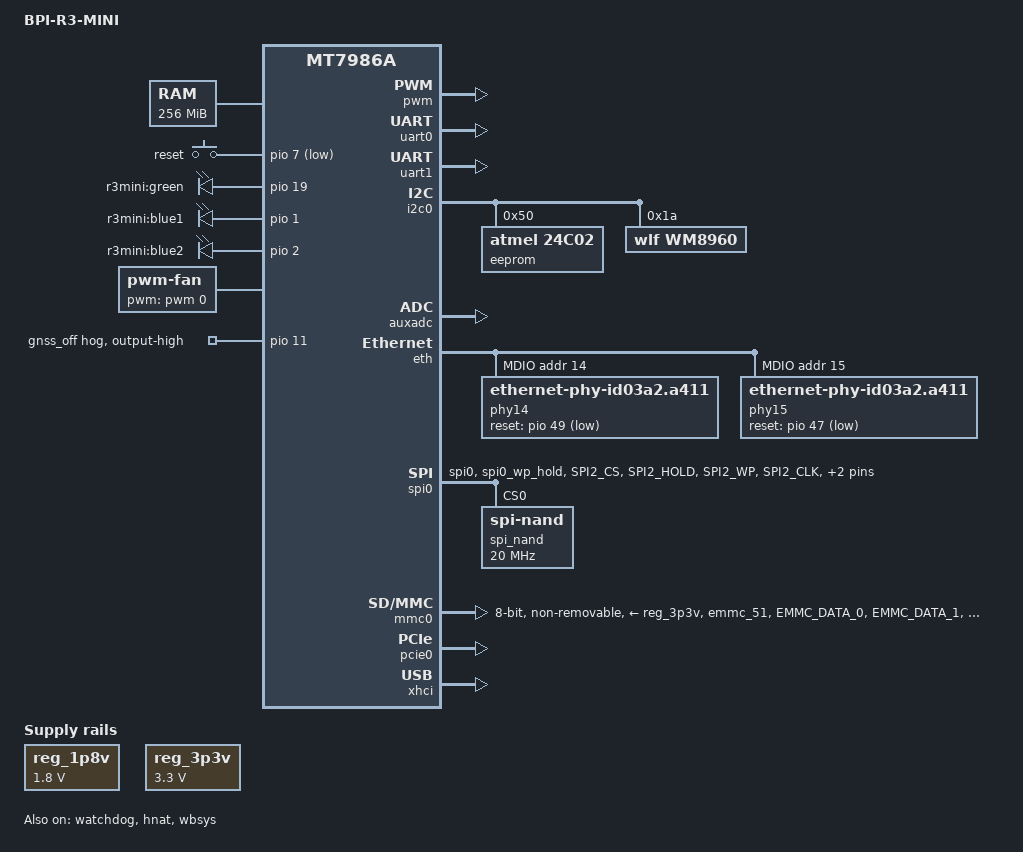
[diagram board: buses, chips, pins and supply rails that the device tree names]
/dts-v1/;
#include "mt7986a.dtsi"
#include "mt7986a-pinctrl.dtsi"
#include <dt-bindings/input/input.h>
#include <dt-bindings/gpio/gpio.h>
/ {
	model = "BPI-R3-MINI";
	compatible = "bananapi,bpi-r3mini-emmc", "mediatek,mt7986a";

	aliases {
		led-boot = &status_led;
		led-failsafe = &status_led;
		led-running = &status_led;
		led-upgrade = &status_led;
	};

	chosen {
		bootargs = "console=ttyS0,115200n1 loglevel=8 \
		earlycon=uart8250,mmio32,0x11002000 \
		root=PARTLABEL=rootfs rootwait rootfstype=squashfs,f2fs";
	};

	memory {
		reg = <0 0x40000000 0 0x10000000>;
	};

	gpio-keys {
		compatible = "gpio-keys";

		button-reset {
			label = "reset";
			linux,code = <KEY_RESTART>;
			gpios = <&pio 7 GPIO_ACTIVE_LOW>;
		};
	};

	leds {
		compatible = "gpio-leds";

		status_led: green {
			label = "r3mini:green";
			gpios = <&pio 19 GPIO_ACTIVE_HIGH>;
		};

		led-1 {
			label = "r3mini:blue1";
			gpios = <&pio 1 GPIO_ACTIVE_HIGH>;
			default-state = "on";
		};

		led-2 {
			label = "r3mini:blue2";
			gpios = <&pio 2 GPIO_ACTIVE_HIGH>;
			default-state = "on";
		};
	};

	fan: pwm-fan {
		compatible = "pwm-fan";
		#cooling-cells = <2>;
		cooling-levels = <0 64 128 192>;
		pwms = <&pwm 0 10000 0>;
		status = "okay";
	};

        reg_1p8v: regulator-1p8v {
                compatible = "regulator-fixed";
                regulator-name = "fixed-1.8V";
                regulator-min-microvolt = <1800000>;
                regulator-max-microvolt = <1800000>;
                regulator-boot-on;
                regulator-always-on;
        };

        reg_3p3v: regulator-3p3v {
                compatible = "regulator-fixed";
                regulator-name = "fixed-3.3V";
                regulator-min-microvolt = <3300000>;
                regulator-max-microvolt = <3300000>;
                regulator-boot-on;
                regulator-always-on;
        };

	sound {
		compatible = "mediatek,mt7986-wm8960-machine";
		mediatek,platform = <&afe>;
		audio-routing = "Headphone", "HP_L",
				"Headphone", "HP_R",
				"LINPUT1", "AMIC",
				"RINPUT1", "AMIC";
		mediatek,audio-codec = <&wm8960>;
		status = "okay";
	};
};

&pwm {
	pinctrl-names = "default";
	pinctrl-0 = <&pwm0_pin &pwm1_pin_g1>;
	status = "okay";
};

&uart0 {
	status = "okay";
};

&uart1 {
	pinctrl-names = "default";
	pinctrl-0 = <&uart1_pins>;
	status = "okay";
};

&uart2 {
	pinctrl-names = "default";
	pinctrl-0 = <&uart2_pins>;
	status = "disabled";
};

&i2c0 {
	pinctrl-names = "default";
	pinctrl-0 = <&i2c_pins>;
	status = "okay";

	/* MAC Address EEPROM */
        eeprom@50 {
                compatible = "atmel,24c02";
                reg = <0x50>;

                address-bits = <8>;
                page-size = <8>;
                size = <256>;
        };

	wm8960: wm8960@1a {
		compatible = "wlf,wm8960";
		reg = <0x1a>;
	};
};

&auxadc {
	status = "okay";
};

&watchdog {
	status = "okay";
};

&cpu_thermal {
	trips {
		cpu_trip_critical: critical {
			temperature = <95000>;
			hysteresis = <2000>;
			type = "critical";
		};

		cpu_trip_hot: hot {
			temperature = <40000>;
			hysteresis = <2000>;
			type = "hot";
		};

		cpu_trip_active: active {
			temperature = <35000>;
			hysteresis = <2000>;
			type = "active";
		};

		cpu_trip_passive: passive {
			temperature = <20000>;
			hysteresis = <2000>;
			type = "passive";
		};
	};

	cooling-maps {
		cpu-active-high {
			cooling-device = <&fan 3 3>;
			trip = <&cpu_trip_critical>;
		};

		cpu-active-low {
			cooling-device = <&fan 2 2>;
			trip = <&cpu_trip_hot>;
		};

		cpu-active {
			cooling-device = <&fan 1 1>;
			trip = <&cpu_trip_active>;
		};

		cpu-passive {
			cooling-device = <&fan 0 0>;
			trip = <&cpu_trip_passive>;
		};
	};
};

&eth {
	status = "okay";

	gmac0: mac@0 {

		compatible = "mediatek,eth-mac";
		reg = <0>;
		phy-mode = "2500base-x";

		fixed-link {
			speed = <2500>;
			full-duplex;
			pause;
		};
	};

	gmac1: mac@1 {

		compatible = "mediatek,eth-mac";
		reg = <1>;
		phy-mode = "2500base-x";

		fixed-link {
			speed = <2500>;
			full-duplex;
			pause;
		};
	};

	mdio: mdio-bus {
		#address-cells = <1>;
		#size-cells = <0>;

		phy14: phy@14 {
			/* EN8811H PHY ID */
			compatible = "ethernet-phy-id03a2.a411";
			/* PHY Address */
			reg = <14>;
			reset-gpios = <&pio 49 1>;     /* GPIO49 */
			reset-assert-us = <10000>;
			reset-deassert-us = <20000>;
			phy-mode = "2500base-x";
			full-duplex;
			pause;
		};

		phy15: phy@15 {
			/* EN8811H PHY ID */
			compatible = "ethernet-phy-id03a2.a411";
			/* PHY Address */
			reg = <15>;
			reset-gpios = <&pio 47 1>;     /* GPIO47 */
			reset-assert-us = <10000>;
			reset-deassert-us = <20000>;
			phy-mode = "2500base-x";
			full-duplex;
			pause;
		};
	};
};

&hnat {
	mtketh-wan = "eth1";
	mtketh-lan = "eth0";
	mtketh-max-gmac = <2>;
	status = "okay";
};

&spi0 {
	pinctrl-names = "default";
	pinctrl-0 = <&spi_flash_pins>;
	status = "okay";

	spi_nand: flash@0 {
		#address-cells = <1>;
		#size-cells = <1>;
		compatible = "spi-nand";
		reg = <0>;
		spi-max-frequency = <20000000>;
		spi-tx-bus-width = <4>;
		spi-rx-bus-width = <4>;
	};
};

&spi1 {
	pinctrl-names = "default";
	pinctrl-0 = <&spic_pins_g2>;
	status = "disabled";
};

&mmc0 {
        pinctrl-names = "default", "state_uhs";
        pinctrl-0 = <&mmc0_pins_default>;
        pinctrl-1 = <&mmc0_pins_uhs>;
        bus-width = <8>;
        max-frequency = <200000000>;
        cap-mmc-highspeed;
        mmc-hs200-1_8v;
        mmc-hs400-1_8v;
        hs400-ds-delay = <0x14014>;
        vmmc-supply = <&reg_3p3v>;
        vqmmc-supply = <&reg_1p8v>;
        non-removable;
        no-sd;
        no-sdio;
        status = "okay";
};

&pcie0 {
	pinctrl-names = "default";
	pinctrl-0 = <&pcie0_pins>;
	status = "okay";
};

&wbsys {
	status = "okay";
	mediatek,eeprom-data = <0x86790200 0x000c4326 0x60000000 0x00000000 0x00000000 0x00000000 0x00000000 0x00000000
		0x00000000 0x00000000 0x00000000 0x00000000 0x00000000 0x00000000 0x00000000 0x00000000
		0x00000000 0x00000000 0x00000000 0x00000000 0x00000000 0x00000000 0x00000000 0x00000000
		0x00000000 0x00000000 0x00000000 0x00000000 0x00000000 0x00000000 0x00000000 0x00000000
		0x00000000 0x00000000 0x00000000 0x00000000 0x00000000 0x00000000 0x00000000 0x00000000
		0x00000000 0x00000000 0x00000000 0x00000000 0x00000000 0x00000000 0x00000000 0x00000000
		0x00000000 0x00000000 0x00000000 0x00000000 0x00000000 0x00000000 0x00000000 0x00000000
		0x00000000 0x00000000 0x00000000 0x00000000 0x00000000 0x00000000 0x00000000 0x00000000
		0x00000000 0x00000000 0x00000000 0x00000000 0x00000000 0x00000000 0x00000000 0x00000000
		0x00000000 0x00000000 0x00000000 0x00000000 0x00000000 0x00000000 0x00000000 0x00000000
		0x00000000 0x00000000 0x00000000 0x00000000 0x00000000 0x00000000 0x00000000 0x00000000
		0x00000000 0x00000000 0x00000000 0x00000000 0x00000000 0x00000000 0x00000000 0x00000000
		0x00000000 0x00000000 0x00000000 0x00000000 0x125b486c 0x00280000 0x05d00000 0x00000000
		0x00000000 0x00000000 0x00000000 0x00000000 0x00000000 0x00000000 0x00000000 0x00000000
		0x00000000 0x00000000 0x00000000 0x00000000 0x00000000 0x00000000 0x00000000 0x00000000
		0x00000000 0x00000000 0x00000000 0x00000000 0x00000000 0x00000000 0x00000000 0x00000000
		0x00000000 0x00000000 0x00000000 0x00000000 0x00000000 0x00000000 0x00000000 0x00000000
		0x00000000 0x00000000 0x00000000 0x00000000 0x00000000 0x00000000 0x00000000 0x00000000
		0x00000000 0x00000000 0x00000000 0x00000000 0x00000000 0x00000000 0x00000000 0x00000000
		0x00000000 0x00000000 0x00000000 0x00000000 0x0c000000 0x00000000 0x00000000 0x00000000
		0x00000000 0x00000000 0x00000000 0x00000000 0x00000000 0x00000000 0x00000000 0x00000000
		0x00000000 0x00000000 0x00000000 0x00000000 0x00000000 0x00000000 0x00000000 0x00000000
		0x00000000 0x00000000 0x00000000 0x00000000 0x00000000 0x00000000 0x00000000 0x00000000
		0x00000000 0x00000000 0x00000000 0x00000000 0x00000000 0x00000000 0x00000000 0x00000000
		0x00000000 0x00000000 0x00000000 0x00000000 0x00000000 0x00000000 0x00000000 0x00000000
		0x00000000 0x00000000 0x00000000 0x00000000 0x00000000 0x00000000 0x00000000 0x00000000
		0x00000000 0x00000000 0x00000000 0x00000000 0x00000000 0x00000000 0x00000000 0x00000000
		0x00000000 0x00000000 0x00000000 0x00000000 0x00000000 0x00000000 0x00000000 0x00000000
		0x00000000 0x00000000 0x00000000 0x00000000 0x00000000 0x00000000 0x00000000 0x00000000
		0x00000000 0x00000000 0x00000000 0x00000000 0x00000000 0x00000000 0x00000000 0x00000000
		0x00000000 0x00000000 0x00000000 0x00000000 0x00000000 0x00000000 0x00000000 0x00000000
		0x00000000 0x00000012 0x12120000 0x00000000 0x00000000 0x00002222 0x22223333 0x33333333
		0x33333333 0x33333333 0x33333333 0x33333333 0x33333333 0x33330000 0x00000000 0x00000000
		0x00000000 0x00000000 0x00000000 0x00000000 0x00000000 0x00000000 0x00000000 0x00000000
		0x002b2b2b 0x2b2d2d2d 0x2d2d2d2d 0x2d2d2d2d 0x2d2d2d2d 0x2d2d2d2d 0x2d000000 0x00000000
		0x00000000 0x00242424 0x24222222 0x22242424 0x24222222 0x22242424 0x24222222 0x22242424
		0x24222222 0x22000000 0x00000000 0x00000000 0x00000000 0x00000000 0x00000000 0x00000000
		0x00000000 0x00000000 0x00000000 0x00000000 0x00000000 0x00000000 0x00000000 0x00000000
		0x00000000 0x00000000 0x00000000 0x00000000 0x00000000 0x00000000 0x00000000 0x00000000
		0x00000000 0x00000000 0x00000000 0x00000000 0x00000000 0x00000000 0x00000000 0x00000000
		0x00000000 0x00000000 0x00000000 0x00000000 0x00000000 0x00000000 0x00000000 0x00000000
		0x00000000 0x00000000 0x00000000 0x00000000 0x00000000 0x00000000 0x00000000 0x00000000
		0x00000000 0x00000000 0x00000000 0x00000000 0x00000000 0x00000000 0x00000000 0x00000000
		0x00000000 0x00000000 0x00000000 0x00000000 0x00000000 0x00000000 0x00000000 0x00000000
		0x00000000 0x007f7f7f 0xd1d1dddd 0xe9e9f5f5 0x01010909 0x1515d1d1 0xdddde9e9 0xf5f5fdfd
		0x09091515 0xd1d1dddd 0xe9e9f5f5 0xfdfd0909 0x1515d1d1 0xdddde9e9 0xf5f5fdfd 0x09091515
		0x00000000 0x00000000 0x00000000 0x00000000 0x00000000 0x00000000 0x00000000 0x00000000
		0x00000000 0x00000000 0x00000000 0x00000000 0x00000000 0x00000000 0x00000000 0x00000000
		0x0efefc00 0x00000000 0x00000000 0x00000000 0x00000000 0x00000000 0x00000000 0x00000000
		0x00000000 0x00000000 0x00000000 0x00000000 0x00000000 0x00000000 0x00000000 0x00000000
		0x00000000 0x00000000 0x00000000 0x00000000 0x00000000 0x00000000 0x00000000 0x00000000
		0x00000000 0x00000000 0x00000000 0x00000000 0x00000000 0x00000000 0x00000000 0x00000000
		0x00000000 0x00000000 0x00000000 0x00000000 0x00000000 0x00000000 0x00000000 0x00000000
		0x00000000 0x00000000 0x00000000 0x00000000 0x00000000 0x00000000 0x00000000 0x00000000
		0x00000000 0x00000000 0x00000000 0x00000000 0x00000000 0x00000000 0x00000000 0x00000000
		0x00000000 0x00000000 0x00000000 0x00000000 0x00000000 0x00000000 0x00000000 0x00000000
		0x00000000 0x00000000 0x00000000 0x00000000 0x00000000 0x00000000 0x00000000 0x00000000
		0x00000000 0x00000000 0x00000000 0x00000000 0x00000000 0x00000000 0x00000000 0x00000000
		0x00000000 0x00000000 0x00000000 0x00000000 0x00000000 0x00000000 0x00000000 0x00000000
		0x00000000 0x00000000 0x00000000 0x00000000 0x00000000 0x00000000 0x00000000 0x00000000
		0x00000000 0x00000000 0x00000000 0x00000000 0x021e021e 0x02000200 0x02370237 0x02370237
		0x02370237 0x02370237 0x02370237 0x02370237 0x02370237 0x02370237 0x02370237 0x02370237
		0x02370237 0x02370237 0x02370237 0x02370237 0x002200c6 0xc6c4c4c3 0x0000c1c2 0xc1838383
		0x838686c1 0xc1838383 0x838686c2 0xc1c18181 0x82838585 0x8686c1c1 0x81818283 0x85858686
		0xc1c18181 0x82838585 0x8686c1c1 0x81818283 0x85858686 0xc1c18181 0x82838585 0x8686c5c5
		0xc3c100c2 0xc3c2c200 0x81828383 0xc2c2c200 0x81828383 0xc3c1c1c1 0x81828384 0x84c2c2c2
		0xc2008182 0x83838585 0xc2c2c200 0x81828383 0x8585c1c1 0xc1818283 0x84848686 0x82828484
		0x85868787 0x8989c2c2 0xc2008182 0x83838585 0xc2c2c200 0x81828383 0x8585c2c2 0xc2008182
		0x83838585 0xc4c4c2c1 0x00c3c3c3 0xc1008183 0x838686c3 0xc3c3c100 0x81838386 0x86c2c2c2
		0x00818284 0x84868682 0x82828485 0x8688888b 0x8bc3c3c3 0xc1008183 0x838686c3 0xc3c3c100
		0x81838386 0x86c3c3c3 0xc1008183 0x83868600 0x00000000 0x00000000 0x00000000 0x00000000
		0x00000000 0x00000000 0x00000000 0x00000000 0x00000000 0x00000000 0x00000000 0x00000000
		0x00000000 0x00000000 0x00000000 0x00000000 0x00000000 0x00000000 0x00000000 0x00000000
		0x00000000 0x00000000 0x00000000 0x00000000 0x00000000 0x00000000 0x00000000 0x00000000
		0x00000000 0x00000000 0x00000000 0x00000000 0x00000000 0x00000000 0x00000000 0x00000000
		0x00000000 0x00000000 0x00000000 0x00000000 0x00000000 0x00000000 0x00000000 0x00000000
		0x00000000 0x00000000 0x00000000 0x00000000 0x00bd0000 0x00000000 0x00000000 0x00000000
		0x00000000 0x00000000 0x00c50000 0x00000000 0x00000000 0x00000000 0x00000000 0x00000000
		0x00000000 0x00000000 0x00000000 0x00000000 0x00000000 0x00000000 0x00000000 0x00000000
		0x00000000 0x00000000 0x00000000 0x00000000 0x00000000 0x00000000 0x00000000 0x00000000
		0x00000000 0x00000000 0x00000000 0x00000000 0x00000000 0x00000000 0x00000000 0x00000000
		0x00495256 0x55555555 0x004a5251 0x51515151 0x004a5355 0x56565656 0x0049504e 0x51515151
		0x00495150 0x54545454 0x00495051 0x51515151 0x00495251 0x50505050 0x00495251 0x51515151
		0x00495251 0x54545454 0x00495150 0x54545454 0x00495352 0x51515151 0x00495353 0x52525252
		0x00495150 0x50505050 0x00495152 0x54545454 0x00495251 0x53535353 0x00000000 0x00000000
		0x00000000 0x00000000 0x00000000 0x00000000 0x00000000 0x00000000 0x00000000 0x00000000
		0x00000000 0x00000000 0x00000000 0x00000000 0x00000000 0x00000000 0x00000000 0x00000000
		0x00000000 0x00000000 0x00000000 0x00000000 0x00000000 0x00000000 0x00000000 0x00000000
		0x00000000 0x00000000 0x00000000 0x00000000 0xd1d1dddd 0xe9e9f5f5 0xfdfd1414 0x1d1d0000
		0x00000000 0x00000000 0x00000000 0x00000000 0x00000000 0x00000000 0x00000000 0x00000000
		0x00000000 0x00000000 0x00000000 0x00000000 0x00000000 0x00000000 0x00000000 0x00000000
		0x00000000 0x00000000 0x00000000 0x00000000 0x00000000 0x00000000 0x00000000 0x00000000
		0x00000000 0x00000000 0x00000000 0x00000000 0x00000000 0x00000000 0x00000000 0x00000000
		0x00000000 0x00000000 0x00000000 0x00000000 0x00000000 0x00000000 0x00000000 0x00000000
		0x00000000 0x00000000 0x00000000 0x00000000 0x00000000 0x00000000 0x00000000 0x00000000
		0x00000000 0x00000000 0x00000000 0x00000000 0x00000000 0x00000000 0x00000000 0x00000000
		0x00000000 0x00000000 0x00000000 0x00000000 0x00000000 0x00000000 0x00000000 0x00000000
		0x00000000 0x00000000 0x00000000 0x00000000 0x00000000 0x00000000 0x00000000 0x00000000
		0x00000000 0x00000000 0x00000000 0x00000000 0x00000000 0x00000000 0x00000000 0x00000000
		0x00000000 0x00000000 0x00000000 0x00000000 0x00000000 0x00000000 0x00000000 0x00000000
		0x00000000 0x00000000 0x00000000 0x00000000 0x00000000 0x00000000 0x00000000 0x00000000
		0x85840000 0xc3c4c382 0x828281c1 0xc4c5c400 0x0000c1c3 0xc4c4c481 0x8181c1c2 0x00000000
		0x00000000 0x00000000 0x00000000 0x00000000 0x00000000 0x00000000 0x00000000 0x00000000
		0x00000000 0x00000000 0x00000000 0x00000000 0x00000000 0x00000000 0x00000000 0x00000000
		0xc0bbc0bb 0xc0bbc0bb 0x40c5c0c4 0xc0c3c0c3 0x40c340c5 0x40c4c0c3 0x40c3c0c2 0xc0c5c0c4
		0x40c440c4 0xc0c3c0c5 0xc0c440c4 0x40c4c0c3 0x00000000 0x00000000 0x00000000 0x00000000
		0x00000000 0x00000000 0x40c640c6 0x40c640c6 0x40c640c6 0x40c640c6 0x40c640c6 0x40c640c6
		0x40c640c6 0x40c640c6 0x40c640c6 0x40c640c6 0x40c640c6 0x40c640c6 0x40c640c6 0x40c640c6
		0x40c640c6 0x40c640c6 0x00000000 0x00000000 0x00000000 0x00000000 0x00000000 0x00000000
		0x00000000 0x00000000 0x00000000 0x00000000 0x00000000 0x00000000 0x00000000 0x00000000
		0x00000000 0x00000000 0x00000000 0x00000000 0x00000000 0x00000000 0x00000000 0x00000000
		0x00000000 0x00000000 0x00000000 0x00000000 0x00000000 0x00000000 0x00000000 0x00000000
		0x00000000 0x00000000 0x00000000 0x00000000 0x00000000 0x00000000 0x00000000 0x00000000
		0x00000000 0x00000000 0x00000000 0x00000000 0x00000000 0x00000000 0x00000000 0x00000000
		0x00000000 0x00000000 0x00000000 0x00000000 0x00000000 0x00000000 0x00000000 0x00000000
		0x00000000 0x00000000 0x00000000 0x00000000 0x00000000 0x00000000 0x00000000 0x00000000
		0x00000000 0x00000000 0x00000000 0x00000000 0x00000000 0x00000000 0x00000000 0x00000000
		0x00000000 0x00000000 0x00000000 0x00000000 0x00000000 0x00000000 0x00000000 0x00000000
		0x00000000 0x00000000 0x00000000 0x00000000 0x00000000 0x00000000 0x00000000 0x00000000
		0x00000000 0x00000000 0x00000000 0x00000000 0x00000000 0x00000000 0x00000000 0x00000000
		0x00000000 0x00000000 0x00000000 0x00000000 0x00000000 0x00000000 0x00000000 0x00000000
		0x00000000 0x00000000 0x00000000 0x00000000 0x00000000 0x00000000 0x00000000 0x00000000
		0x00000000 0x00000000 0x00000000 0x00000000 0x00000000 0x00000000 0x00000000 0x00000000
		0x00000000 0x00000000 0x00000000 0x00000000 0x00000000 0x00000000 0x00000000 0x00000000
		0x00000000 0x00000000 0x00000000 0x00000000 0x00000000 0x00000000 0x00000000 0x00000000
		0x00000000 0x00000000 0x00000000 0x00000000 0x00000000 0x00000000 0x00000000 0x00000000
		0x00000000 0x00000000 0x00000000 0x00000000 0x00000000 0x00000000 0x00000000 0x00000000
		0x00000000 0x00000000 0x00000000 0x00000000 0x00000000 0x00000000 0x00000000 0x00000000>;
};

/*
&wbsys {
	mediatek,mtd-eeprom = <&factory 0x0000>;
	status = "okay";
	pinctrl-names = "default", "dbdc";
	pinctrl-0 = <&wf_2g_5g_pins>;
	pinctrl-1 = <&wf_dbdc_pins>;
};
*/

&pio {
	/* GPIO 11 NGFF_GNSS_OFF. output-high: enable, output-low: disable */
	gnss_off {
		gpio-hog;
		gpios = <11 GPIO_ACTIVE_HIGH>;
		output-high;
	};

        mmc0_pins_default: mmc0-pins-50-to-61-default {
                mux {
                        function = "flash";
                        groups = "emmc_51";
                };
                conf-cmd-dat {
                        pins = "EMMC_DATA_0", "EMMC_DATA_1", "EMMC_DATA_2",
                               "EMMC_DATA_3", "EMMC_DATA_4", "EMMC_DATA_5",
                               "EMMC_DATA_6", "EMMC_DATA_7", "EMMC_CMD";
                        input-enable;
                        drive-strength = <MTK_DRIVE_4mA>;
                        mediatek,pull-up-adv = <1>;     /* pull-up 10K */
                };
                conf-clk {
                        pins = "EMMC_CK";
                        drive-strength = <MTK_DRIVE_6mA>;
                        mediatek,pull-down-adv = <2>;   /* pull-down 50K */
                };
                conf-ds {
                        pins = "EMMC_DSL";
                        mediatek,pull-down-adv = <2>;   /* pull-down 50K */
                };
                conf-rst {
                        pins = "EMMC_RSTB";
                        drive-strength = <MTK_DRIVE_4mA>;
                        mediatek,pull-up-adv = <1>;     /* pull-up 10K */
                };
        };

        mmc0_pins_uhs: mmc0-pins-50-to-61-uhs {
                mux {
                        function = "flash";
                        groups = "emmc_51";
                };
                conf-cmd-dat {
                        pins = "EMMC_DATA_0", "EMMC_DATA_1", "EMMC_DATA_2",
                               "EMMC_DATA_3", "EMMC_DATA_4", "EMMC_DATA_5",
                               "EMMC_DATA_6", "EMMC_DATA_7", "EMMC_CMD";
                        input-enable;
                        drive-strength = <MTK_DRIVE_4mA>;
                        mediatek,pull-up-adv = <1>;     /* pull-up 10K */
                };
                conf-clk {
                        pins = "EMMC_CK";
                        drive-strength = <MTK_DRIVE_6mA>;
                        mediatek,pull-down-adv = <2>;   /* pull-down 50K */
                };
                conf-ds {
                        pins = "EMMC_DSL";
                        mediatek,pull-down-adv = <2>;   /* pull-down 50K */
                };
                conf-rst {
                        pins = "EMMC_RSTB";
                        drive-strength = <MTK_DRIVE_4mA>;
                        mediatek,pull-up-adv = <1>;     /* pull-up 10K */
                };
        };

	spi_flash_pins: spi-flash-pins-33-to-38 {
		mux {
			function = "flash";
			groups = "spi0", "spi0_wp_hold";
		};
		conf-pu {
			pins = "SPI2_CS", "SPI2_HOLD", "SPI2_WP";
			drive-strength = <MTK_DRIVE_8mA>;
			mediatek,pull-up-adv = <0>;	/* bias-disable */
		};
		conf-pd {
			pins = "SPI2_CLK", "SPI2_MOSI", "SPI2_MISO";
			drive-strength = <MTK_DRIVE_8mA>;
			mediatek,pull-down-adv = <0>;	/* bias-disable */
		};
	};

	wf_2g_5g_pins: wf_2g_5g-pins {
		mux {
			function = "wifi";
			groups = "wf_2g", "wf_5g";
		};
		conf {
			pins = "WF0_HB1", "WF0_HB2", "WF0_HB3", "WF0_HB4",
			       "WF0_HB0", "WF0_HB0_B", "WF0_HB5", "WF0_HB6",
			       "WF0_HB7", "WF0_HB8", "WF0_HB9", "WF0_HB10",
			       "WF0_TOP_CLK", "WF0_TOP_DATA", "WF1_HB1",
			       "WF1_HB2", "WF1_HB3", "WF1_HB4", "WF1_HB0",
			       "WF1_HB5", "WF1_HB6", "WF1_HB7", "WF1_HB8",
			       "WF1_TOP_CLK", "WF1_TOP_DATA";
			drive-strength = <MTK_DRIVE_4mA>;
		};
	};

	wf_dbdc_pins: wf_dbdc-pins {
		mux {
			function = "wifi";
			groups = "wf_dbdc";
		};
		conf {
			pins = "WF0_HB1", "WF0_HB2", "WF0_HB3", "WF0_HB4",
			       "WF0_HB0", "WF0_HB0_B", "WF0_HB5", "WF0_HB6",
			       "WF0_HB7", "WF0_HB8", "WF0_HB9", "WF0_HB10",
			       "WF0_TOP_CLK", "WF0_TOP_DATA", "WF1_HB1",
			       "WF1_HB2", "WF1_HB3", "WF1_HB4", "WF1_HB0",
			       "WF1_HB5", "WF1_HB6", "WF1_HB7", "WF1_HB8",
			       "WF1_TOP_CLK", "WF1_TOP_DATA";
			drive-strength = <MTK_DRIVE_4mA>;
		};
	};
};

&xhci {

	status = "okay";
};

/* BPI-R3 Mini uses the primary WED instance for its internal DBDC radio. */
&wed2 {
	status = "disabled";
};
